# spi_flash_ctrl_model: IP-XACT component
VLNV IcronTechnologies:IcronTechnologies:spi_flash_ctrl_model:1.0

## Parameters
addr_width = 8
bus_width = 32

## Bus interfaces (logical=physical port)
default_map: slave AGNISYS:AGNISYS:APB:1.0, memory map spi_flash_ctrlmap
  pclk=pclk, presetn=presetn, psel=psel, penable=penable, pwrite=pwrite, pprot=pprot, pstrb=pstrb, pwdata=pwdata, paddr=paddr, pready=pready, prdata=prdata, pslverr=pslverr

## Ports
in pclk
in presetn
in psel
in penable
in pwrite
in pprot[2:0]
in pstrb[(bus_width div 8 )-1:0]
in pwdata[bus_width -1:0]
in paddr[addr_width -1:0]
out pready
out prdata[bus_width -1:0]
out pslverr
out spi_flash_ctrl_regsversion_major_r[7:0]
out spi_flash_ctrl_regsversion_minor_r[7:0]
out spi_flash_ctrl_regsversion_patch_r[7:0]
out spi_flash_ctrl_regsgeneric_cfg_enb
out spi_flash_ctrl_regsgeneric_cfg_sck_freerun_r
out spi_flash_ctrl_regsgeneric_cfg_io_out_defaults_r[3:0]
out spi_flash_ctrl_regsgeneric_cfg_io_tri_defaults_r[3:0]
out spi_flash_ctrl_regsgeneric_cfg_sck_oe_deassert_cfg_r[3:0]
out spi_flash_ctrl_regsgeneric_cfg_cs_deassert_cfg_r[3:0]
out spi_flash_ctrl_regsgeneric_cfg_sck_oe_assert_cfg_r[3:0]
out spi_flash_ctrl_regsgeneric_cfg_cs_assert_cfg_r[3:0]
out spi_flash_ctrl_regsaddr_offset_enb
out spi_flash_ctrl_regsaddr_offset_val_r[31:0]
out spi_flash_ctrl_regsaddr_enb
out spi_flash_ctrl_regsaddr_val_r[31:0]
out spi_flash_ctrl_regsbasic_cfg_enb
out spi_flash_ctrl_regsbasic_cfg_tr_gap_p3_r[15:0]
out spi_flash_ctrl_regsbasic_cfg_io_mask_data_r[3:0]
out spi_flash_ctrl_regsbasic_cfg_io_mask_addr_r[3:0]
out spi_flash_ctrl_regsbasic_cfg_io_mask_cmd_r[3:0]
out spi_flash_ctrl_regscontrol_enb
out spi_flash_ctrl_regscontrol_go_r
in spi_flash_ctrl_regscontrol_go_hw_clear
out spi_flash_ctrl_regscontrol_addr_mode_r
out spi_flash_ctrl_regscontrol_write_r
out spi_flash_ctrl_regscontrol_num_dummy_clks_r[6:0]
out spi_flash_ctrl_regscontrol_num_bytes_r[7:0]
out spi_flash_ctrl_regscontrol_cmd_r[7:0]
out spi_flash_ctrl_regswr_data_enb
out spi_flash_ctrl_regswr_data_val_r[31:0]
out spi_flash_ctrl_regsregwr_data_val_wr_pulse
in spi_flash_ctrl_regsrd_data_val_in[31:0]
in spi_flash_ctrl_regsrd_data_val_in_enb
out spi_flash_ctrl_regsrd_data_val_rd_pulse
out spi_flash_ctrl_regsin_fifo_enb
out spi_flash_ctrl_regsin_fifo_fifo_clear_r
out spi_flash_ctrl_regsregin_fifo_fifo_clear_wr_pulse
in spi_flash_ctrl_regsin_fifo_fifo_af_in
in spi_flash_ctrl_regsin_fifo_fifo_af_in_enb
in spi_flash_ctrl_regsin_fifo_fifo_ae_in
in spi_flash_ctrl_regsin_fifo_fifo_ae_in_enb
in spi_flash_ctrl_regsin_fifo_fifo_full_in
in spi_flash_ctrl_regsin_fifo_fifo_full_in_enb
in spi_flash_ctrl_regsin_fifo_fifo_empty_in
in spi_flash_ctrl_regsin_fifo_fifo_empty_in_enb
out spi_flash_ctrl_regsin_fifo_fifo_aft_r[7:0]
out spi_flash_ctrl_regsin_fifo_fifo_aet_r[7:0]
in spi_flash_ctrl_regsin_fifo_fifo_depth_in[7:0]
in spi_flash_ctrl_regsin_fifo_fifo_depth_in_enb
out spi_flash_ctrl_regsout_fifo_enb
out spi_flash_ctrl_regsout_fifo_fifo_clear_r
out spi_flash_ctrl_regsregout_fifo_fifo_clear_wr_pulse
in spi_flash_ctrl_regsout_fifo_fifo_af_in
in spi_flash_ctrl_regsout_fifo_fifo_af_in_enb
in spi_flash_ctrl_regsout_fifo_fifo_ae_in
in spi_flash_ctrl_regsout_fifo_fifo_ae_in_enb
in spi_flash_ctrl_regsout_fifo_fifo_full_in
in spi_flash_ctrl_regsout_fifo_fifo_full_in_enb
in spi_flash_ctrl_regsout_fifo_fifo_empty_in
in spi_flash_ctrl_regsout_fifo_fifo_empty_in_enb
out spi_flash_ctrl_regsout_fifo_fifo_aft_r[7:0]
out spi_flash_ctrl_regsout_fifo_fifo_aet_r[7:0]
in spi_flash_ctrl_regsout_fifo_fifo_depth_in[7:0]
in spi_flash_ctrl_regsout_fifo_fifo_depth_in_enb
out spi_flash_ctrl_regsmm_addr_offset_enb
out spi_flash_ctrl_regsmm_addr_offset_val_r[31:0]
out spi_flash_ctrl_regsmm_basic_cfg_enb
out spi_flash_ctrl_regsmm_basic_cfg_addr_mode_r
out spi_flash_ctrl_regsmm_basic_cfg_num_dummy_clks_r[6:0]
out spi_flash_ctrl_regsmm_basic_cfg_tr_gap_p3_r[3:0]
out spi_flash_ctrl_regsmm_basic_cfg_io_mask_data_r[3:0]
out spi_flash_ctrl_regsmm_basic_cfg_io_mask_addr_r[3:0]
out spi_flash_ctrl_regsmm_basic_cfg_io_mask_cmd_r[3:0]
out spi_flash_ctrl_regsmm_basic_cfg_read_cmd_r[7:0]
out spi_flash_ctrl_regsmm_xip_cfg_enb
out spi_flash_ctrl_regsmm_xip_cfg_xip_en_r
out spi_flash_ctrl_regsmm_xip_cfg_io_mask_mode_r[3:0]
out spi_flash_ctrl_regsmm_xip_cfg_num_mode_bits_r[3:0]
out spi_flash_ctrl_regsmm_xip_cfg_mode_xip_r[7:0]
out spi_flash_ctrl_regsmm_xip_cfg_mode_normal_r[7:0]
out spi_flash_ctrl_regsmm_suspend_cfg_enb
out spi_flash_ctrl_regsmm_suspend_cfg_tr_gap_p3_r[15:0]
out spi_flash_ctrl_regsmm_suspend_cfg_enable_r
out spi_flash_ctrl_regsmm_suspend_cfg_io_mask_r[3:0]
out spi_flash_ctrl_regsmm_suspend_cfg_cmd_r[7:0]

## Address spaces and blocks
spi_flash_ctrlmap.spi_flash_ctrl: base 0x000, range 0x100, width 32

## Registers
Registers are 32-bit, read-write, reset 0x0 unless marked. A register's access mark holds for its fields unless they carry their own. Offsets are from the block's base; lines under a group give offsets from that group; [hi:lo] are bit positions; {n}, {i} and the like mark numbered series; 'fields as' and 'values as' point back to an identical list; <NAME> marks a mode.

## spi_flash_ctrlmap.spi_flash_ctrl — SPI Flash Controller
Base 0x00000000
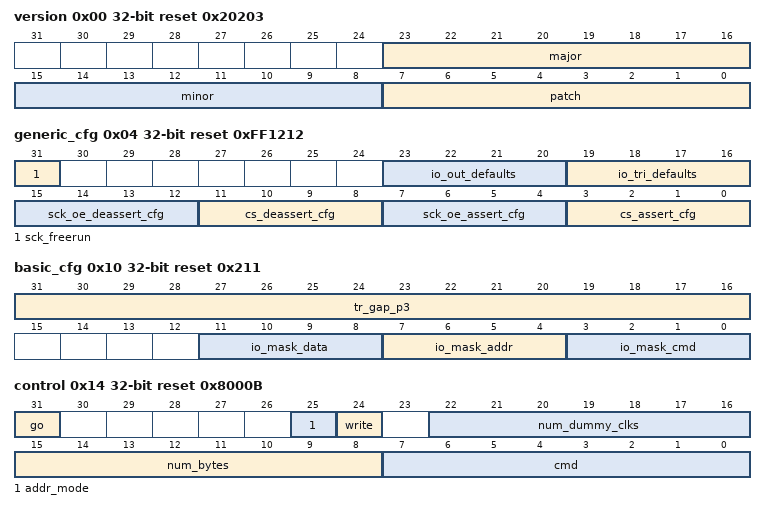
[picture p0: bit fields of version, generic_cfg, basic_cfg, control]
0x00 version ro reset 0x20203
  [23:16] major — Major version
  [15:8] minor — Minor version
  [7:0] patch — Patch version
0x04 generic_cfg reset 0xFF1212 — Basic Configuration
  [31] sck_freerun — SCK Freerun (Active-High)
  [23:20] io_out_defaults — Output value for each IO when not active
  [19:16] io_tri_defaults — Tri-State value for each IO when not active
  [15:12] sck_oe_deassert_cfg — SCK OE deassert configuration 0 : one cycle before last action finish 1 : aligned with last action finish 2-15 : n-1 (1-14) cycles after last action finish
  [11:8] cs_deassert_cfg — CS deassert configuration 0 : one cycle before last action finish 1 : aligned with last action finish 2-15 : n-1 (1-14) cycles after last action finish
  [7:4] sck_oe_assert_cfg — SCK OE assert configuration 0 : one cycle after first action start 1 : aligned with first action start 2-15 : n-1 (1-14) cycles before first action start
  [3:0] cs_assert_cfg — CS assert configuration 0 : one cycle after first action start 1 : aligned with first action start 2-15 : n-1 (1-14) cycles before first action start
0x08 addr_offset — Address Offset
  [31:0] val — Address Offset - This is the offset from the address
0x0C addr — Address
  [31:0] val
0x10 basic_cfg reset 0x211 — Basic Configuration
  [31:16] tr_gap_p3 — Minimum number of SPI clock cycles + 3 that CS should be deasserted after a command
  [11:8] io_mask_data — IO mask for the data - 0 means no data
  [7:4] io_mask_addr — IO mask for the address - 0 means no address
  [3:0] io_mask_cmd — IO mask for the command - 0 means no command
0x14 control reset 0x8000B
  [31] go — Write a 1 to initiate a SPI transaction. HW will clear this field upon completion and also generate an interrupt. A new transaction should not be attempted until this field returns a 0, indicating it is not busy.
  [25] addr_mode — Address mode 0 : 3-bytes 1 : 4-bytes
  [24] write — Read or Write Data (only used if io_mask_data != 0) 0 : Read Data 1 : Write Data
  [22:16] num_dummy_clks — Number of dummy clock cycles - 0 means no dummy clock cycles
  [15:8] num_bytes — Number of data bytes (0 stops when FIFO is full/empty)
  [7:0] cmd — Command
0x18 wr_data wo — Write data
  [31:0] val — Word to write into the output FIFO.
0x1C rd_data ro — Read data
  [31:0] val — Word to read from the input FIFO.
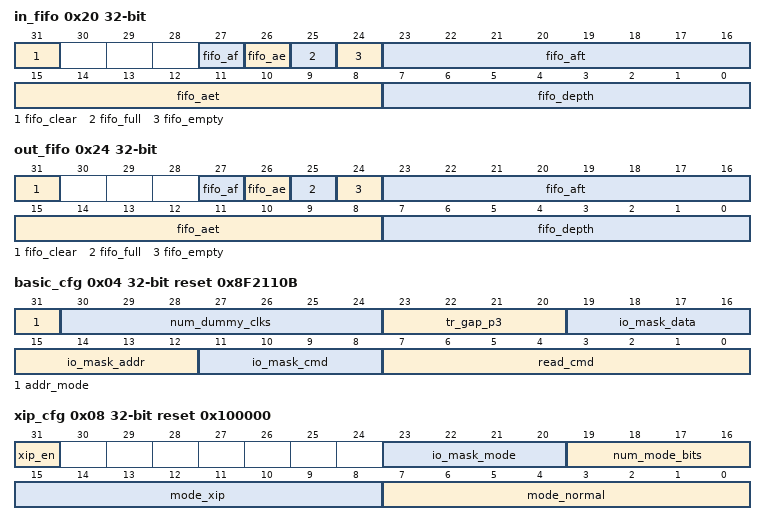
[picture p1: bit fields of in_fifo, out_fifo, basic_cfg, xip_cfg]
0x20 in_fifo access per field — Input FIFO control and status
  [31] fifo_clear rw
  [27] fifo_af ro — FIFO almost full status field. A 1 indicates an almost full or full FIFO. This bit is set when there are between fifo_aft and fifo_depth number of entries in the FIFO.
  [26] fifo_ae ro — FIFO almost empty status field. A 1 indicates an almost empty or empty FIFO. This bit is set when there are between 0 and fifo_aet number of entries in the FIFO.
  [25] fifo_full ro — FIFO full status field. A 1 indicates a full FIFO.
  [24] fifo_empty ro — FIFO empty status field. A 1 indicates an empty FIFO.
  [23:16] fifo_aft rw — FIFO almost full threshold
  [15:8] fifo_aet rw — FIFO almost empty threshold
  [7:0] fifo_depth ro — FIFO depth (always 4 bytes wide)
0x24 out_fifo access per field — Output FIFO control and status
  fields as in_fifo
0x28 mm group — Memory Mapped register group
  0x00 addr_offset — Address Offset
    [31:0] val — Address Offset - This is the offset from the address
  0x04 basic_cfg reset 0x8F2110B — Basic Configuration
    [31] addr_mode — Address mode 0 : 3-bytes 1 : 4-bytes
    [30:24] num_dummy_clks — Number of dummy clock cycles - 0 means no dummy clock cycles
    [23:20] tr_gap_p3 — Minimum number of SPI clock cycles + 3 that CS should be deasserted after a read command
    [19:16] io_mask_data — IO mask for the read data
    [15:12] io_mask_addr — IO mask for the address
    [11:8] io_mask_cmd — IO mask for the read command
    [7:0] read_cmd — Read command
  0x08 xip_cfg reset 0x100000 — eXecute In Place Configuration
    [31] xip_en — XIP Enable - The first read transaction following the assertion of this bit will have the basic_cfg.read_cmd and xip_cfg.mode_xip bits - Following read transactions will not have a read command and will use xip_cfg.mode_xip bits - The read transaction following the de-assertion of this bit will not have a read command and use xip_cfg.mode_normal bits - Following read transactions will use basic_cfg.read_cmd and xip_cfg.mode_normal bits (Default)
    [23:20] io_mask_mode — IO Mask for the mode bits
    [19:16] num_mode_bits — Number of mode bits to send - 0 means no mode bits are sent - 8 is the maximum
    [15:8] mode_xip — Mode bits when there is no command (XIP mode)
    [7:0] mode_normal — Mode bits when there is an command (normal read mode)
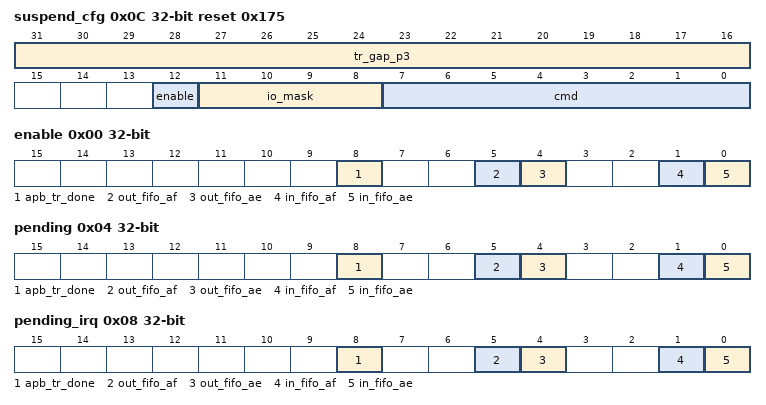
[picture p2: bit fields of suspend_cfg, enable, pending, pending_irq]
  0x0C suspend_cfg reset 0x175 — Suspend Configuration
    [31:16] tr_gap_p3 — Minimum number of SPI clock cycles + 3 that CS should be deasserted after suspend command
    [12] enable — This should be set by SW when a suspend command should be executed before an incoming read request can be handled. This would be the case if a program or erase is in progress. This bit gets cleared as soon as the suspend command is executed.
    [11:8] io_mask — IO Mask for the suspend command
    [7:0] cmd — Suspend command
0x38 irq group — SPI Flash Controller Interrupt register group
  0x00 enable — Interrupt Enable register - Write 1 to enable, 0 to mask an interrupt
    [8] apb_tr_done — APB SPI Flash transaction done
    [5] out_fifo_af — Output FIFO almost full
    [4] out_fifo_ae — Output FIFO almost empty NOTE: If the FIFO is empty when this interrupt is enabled, it will cause an interrupt right away!
    [1] in_fifo_af — Input FIFO almost full
    [0] in_fifo_ae — Input FIFO almost empty interrupt mask - Write 1 to enable NOTE: If the FIFO is empty when this interrupt is enabled, it will cause an interrupt right away!
  0x04 pending — Pending register - This indicates which events are pending, Write 1 to clear
    [8] apb_tr_done write-1-clears — Level-triggered - Active-High APB SPI Flash transaction done
    [5] out_fifo_af write-1-clears — Level-triggered - Active-High Output FIFO almost full
    [4] out_fifo_ae write-1-clears — Level-triggered - Active High Output FIFO almost empty NOTE: If the FIFO is empty, this event is pending and if enabled will cause an interrupt!
    [1] in_fifo_af write-1-clears — Level-triggered - Active-High Input FIFO almost full
    [0] in_fifo_ae write-1-clears — Level-triggered - Active High Input FIFO almost empty NOTE: If the FIFO is empty, this event is pending and if enabled will cause an interrupt!
  0x08 pending_irq ro — Interrupt Pending register - This indicates which pending events are enabled to cause an interrupt
    [8] apb_tr_done — Level-triggered - Active-High APB SPI Flash transaction done
    [5] out_fifo_af — Level-triggered - Active-High Output FIFO almost full
    [4] out_fifo_ae — Level-triggered - Active High Output FIFO almost empty
    [1] in_fifo_af — Level-triggered - Active-High Input FIFO almost full
    [0] in_fifo_ae — Level-triggered - Active High Input FIFO almost empty
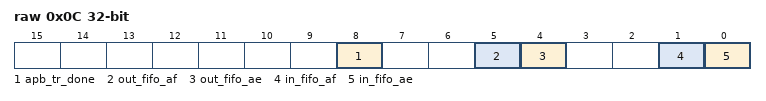
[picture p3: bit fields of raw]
  0x0C raw ro — This register contains the registered state of interrupt signals
    [8] apb_tr_done — Current state of the APB SPI Flash transaction done flag (Active-High)
    [5] out_fifo_af — Current state of the output FIFO almost full flag (Active-High)
    [4] out_fifo_ae — Current state of the output FIFO almost empty flag (Active-High)
    [1] in_fifo_af — Current state of the input FIFO almost full flag (Active-High)
    [0] in_fifo_ae — Current state of the input FIFO almost empty flag (Active-High)
